# MSPM0G350x register map
File version: 1.0
Registers are 32-bit, read-write, no defined reset value unless marked. A register's access mark holds for its fields unless they carry their own. Offsets are from the block's base; lines under a group give offsets from that group; [hi:lo] are bit positions; {n}, {i} and the like mark numbered series; 'fields as' and 'values as' point back to an identical list; <NAME> marks a mode.

## Memory map
0x40018000 DAC0 size 0x1F00 — PERIPHERALREGION
0x400A2000 GPIOB size 0x1F00 — PERIPHERALREGION
0x40440000 CRC size 0x2000 — PERIPHERALREGION

## GPIOB — PERIPHERALREGION
Base 0x400A2000
0x400 FSUB_0 reset 0x0 — Subsciber Port 0
  [3:0] CHANID — 0 = disconnected. 1-15 = connected to channelID = CHANID.
    0=UNCONNECTED (A value of 0 specifies that the event is not connected)
0x800 PWREN — Power enable
  [0] ENABLE — Enable the power
    0=DISABLE (Disable Power); 1=ENABLE (Enable Power)
{0x800+0x18*i} TEST_REG_{i} (i=0..3) — Reg Description
  [0] ENABLE — Enable the reg
    0=DISABLE (Disable regster); 1=ENABLE
0x800 TEST_REG_A — Reg Description
  fields as TEST_REG_0
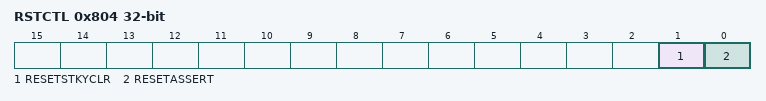
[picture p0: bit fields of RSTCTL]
0x804 RSTCTL wo — Reset Control
  [1] RESETSTKYCLR — Clear the RESETSTKY bit in the STAT register
    0=NOP (Writing 0 has no effect); 1=CLR (Clear reset sticky bit)
  [0] RESETASSERT — Assert reset to the peripheral
    0=NOP (Writing 0 has no effect); 1=ASSERT (Assert reset)
0x814 STAT ro — Status Register
  [16] RESETSTKY — This bit indicates, if the peripheral was reset, since this bit was cleared by RESETSTKYCLR in the RSTCTL register
    0=NORES (The peripheral has not been reset since this bit was last cleared by RESETSTKYCLR in the RSTCTL register); 1=RESET (The peripheral was reset since the last bit clear)
0x818 TEST_REG_B — Reg Description
  fields as TEST_REG_0
0x830 TEST_REG_C — Reg Description
  fields as TEST_REG_0
0x848 TEST_REG_D — Reg Description
  fields as TEST_REG_0
0x1000 TEST_NESTED_CLUSTER_0[{x}] (x=X,Y,Z; step 0x18) group
  0x00 TEST_NC_REG — Reg Description
    fields as TEST_REG_0
0x1000 TEST_NESTED_CLUSTER_A[{x}] (x=X,Y,Z; step 0x18) group
  0x00 TEST_NC_REG — Reg Description
    fields as TEST_REG_0
0x1018 TEST_NESTED_CLUSTER_1[{x}] (x=X,Y,Z; step 0x18) group
  0x00 TEST_NC_REG — Reg Description
    fields as TEST_REG_0
0x1018 TEST_NESTED_CLUSTER_B[{x}] (x=X,Y,Z; step 0x18) group
  0x00 TEST_NC_REG — Reg Description
    fields as TEST_REG_0
0x1030 TEST_NESTED_CLUSTER_2[{x}] (x=X,Y,Z; step 0x18) group
  0x00 TEST_NC_REG — Reg Description
    fields as TEST_REG_0
0x1030 TEST_NESTED_CLUSTER_C[{x}] (x=X,Y,Z; step 0x18) group
  0x00 TEST_NC_REG — Reg Description
    fields as TEST_REG_0
0x1048 TEST_NESTED_CLUSTER_3[{x}] (x=X,Y,Z; step 0x18) group
  0x00 TEST_NC_REG — Reg Description
    fields as TEST_REG_0
0x1048 TEST_NESTED_CLUSTER_D[{x}] (x=X,Y,Z; step 0x18) group
  0x00 TEST_NC_REG — Reg Description
    fields as TEST_REG_0

## DAC0 — PERIPHERALREGION
Base 0x40018000
0x1020 DAC0_IIDX_0 ro reset 0x0 — Interrupt index
  [3:0] STAT — Interrupt index status
    0=NO_INTR (No pending interrupt); 2=MODRDYIFG (Module ready interrupt); 9=FIFOFULLIFG (FIFO full interrupt); 10=FIFO1B4IFG (FIFO one fourth empty interrupt); 11=FIFO1B2IFG (FIFO half empty interrupt); 12=FIFO3B4IFG (FIFO three fourth empty interrupt); 13=FIFOEMPTYIFG (FIFO empty interrupt); 14=FIFOURUNIFG (FIFO underrun interrupt); 15=DMADONEIFG (DMA done interrupt)
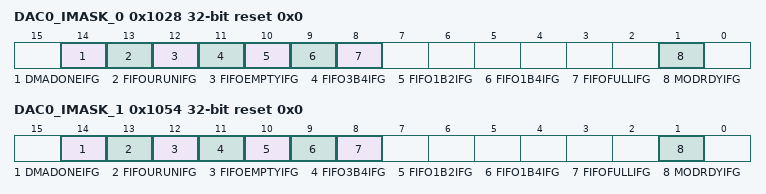
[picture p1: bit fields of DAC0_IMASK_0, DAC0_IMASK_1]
0x1028 DAC0_IMASK_0 reset 0x0 — Interrupt mask
  [all] fields
    0=CLR (Interrupt is masked out); 1=SET (Interrupt will request an interrupt service routine and corresponding bit in MIS will be set)
  [14] DMADONEIFG — Masks DMADONEIFG
  [13] FIFOURUNIFG — Masks FIFOURUNIFG
  [12] FIFOEMPTYIFG — Masks FIFOEMPTYIFG
  [11] FIFO3B4IFG — Masks FIFO3B4IFG
  [10] FIFO1B2IFG — Masks FIFO1B2IFG
  [9] FIFO1B4IFG — Masks FIFO1B4IFG
  [8] FIFOFULLIFG — Masks FIFOFULLIFG
  [1] MODRDYIFG — Masks MODRDYIFG
0x104C DAC0_IIDX_1 ro reset 0x0 — Interrupt index
  fields as DAC0_IIDX_0
0x1054 DAC0_IMASK_1 reset 0x0 — Interrupt mask
  fields as DAC0_IMASK_0

## CRC — PERIPHERALREGION
Base 0x40440000
{0x800+0x18*i} TEST_CLUSTER_WITH_REG_ARRAY_MEMBER[{i}] (i=0..0) group
  0x00 CRC_PWREN reset 0x0 — Power enable
    [0] ENABLE — Enable the power
      0=DISABLE (Disable Power); 1=ENABLE (Enable Power)
  {0x1800+4j} TEST_REGISTER_ARRAY_IN_CLUSTER_{j} (j=0..511) wo reset 0x0 — CRC Input Data Array Register
    [31:0] DATA — Input Data
